CM_ "AUTOGENERATED FILE, DO NOT EDIT";

CM_ "gwm_haval_h6_mk3.dbc starts here";
BO_ 96 CAR_OVERALL_SIGNALS2: 64 XXX
 SG_ CRC1 : 7|8@0+ (1,0) [0|255] "" XXX
 SG_ COUNTER1 : 59|4@0+ (1,0) [0|15] "" XXX
 SG_ CRC2 : 71|8@0+ (1,0) [0|255] "" XXX
 SG_ GAS_POSITION : 79|8@0+ (0.393700787,0) [0|255] "%" XXX
 SG_ BRAKE_SIGNAL : 86|1@0+ (1,0) [0|1] "" XXX
 SG_ ACC_GAS_POSITION : 103|8@0+ (0.393700787,0) [0|255] "%" XXX
 SG_ COUNTER2 : 123|4@0+ (1,0) [0|15] "" XXX
 SG_ CRC3 : 135|8@0+ (1,0) [0|255] "" XXX
 SG_ COUNTER3 : 187|4@0+ (1,0) [0|15] "" XXX

BO_ 147 IMPRECISE_SPEED_INFORMATION: 8 XXX
 SG_ IMPRECISE_SPEED : 15|8@0+ (3.5,0) [0|255] "kph" XXX
 SG_ COUNTER : 59|4@0+ (1,0) [0|15] "" XXX

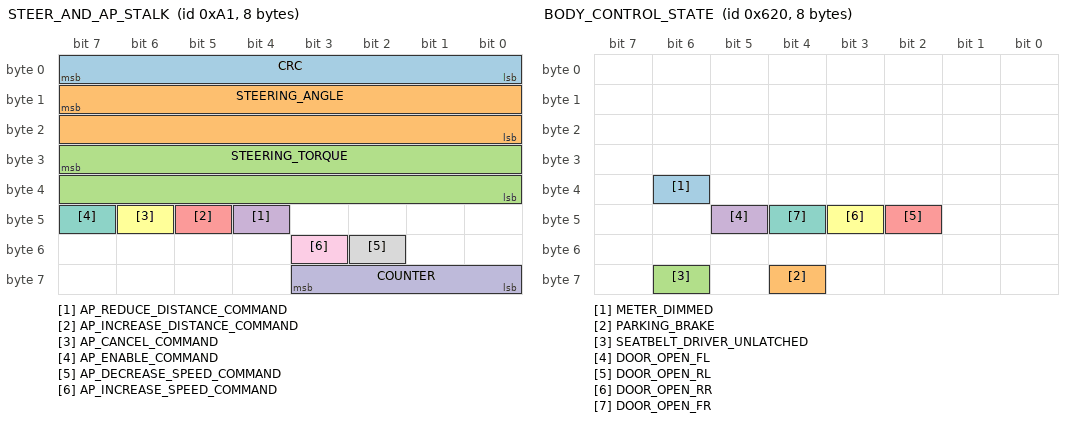
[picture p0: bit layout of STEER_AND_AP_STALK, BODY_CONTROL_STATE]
BO_ 161 STEER_AND_AP_STALK: 8 XXX
 SG_ CRC : 7|8@0+ (1,0) [0|255] "" XXX
 SG_ STEERING_ANGLE : 15|16@0+ (0.05,0) [0|65535] "degs" XXX
 SG_ STEERING_TORQUE : 31|16@0+ (1,0) [0|65535] "??" XXX
 SG_ AP_REDUCE_DISTANCE_COMMAND : 44|1@0+ (1,0) [0|1] "" XXX
 SG_ AP_INCREASE_DISTANCE_COMMAND : 45|1@0+ (1,0) [0|1] "AUTOPILOT_STALK" XXX
 SG_ AP_CANCEL_COMMAND : 46|1@0+ (1,0) [0|1] "" XXX
 SG_ AP_ENABLE_COMMAND : 47|1@0+ (1,0) [0|1] "" XXX
 SG_ AP_DECREASE_SPEED_COMMAND : 50|1@0+ (1,0) [0|1] "" XXX
 SG_ AP_INCREASE_SPEED_COMMAND : 51|1@0+ (1,0) [0|1] "" XXX
 SG_ COUNTER : 59|4@0+ (1,0) [0|255] "" XXX

BO_ 259 SPEED: 64 XXX
 SG_ CRC : 199|8@0+ (1,0) [0|255] "" XXX
 SG_ ODD_GAS_POSITION : 231|8@0+ (1,0) [0|255] "" XXX
 SG_ SPEED : 239|8@0+ (1,0) [0|255] "Khp" XXX
 SG_ COUNTER2 : 251|4@0+ (1,0) [0|15] "" XXX

BO_ 273 UNDEFINED_2: 8 XXX
 SG_ CRC : 7|8@0+ (1,0) [0|255] "" XXX
 SG_ COUNTER : 59|4@0+ (1,0) [0|15] "" XXX

BO_ 288 BRAKE2: 64 XXX
 SG_ CRC : 7|8@0+ (1,0) [0|255] "" XXX
 SG_ ODD_BRAKE_PRESSURE : 39|8@0+ (1,-27) [0|255] "" XXX
 SG_ COUNTER : 59|4@0+ (1,0) [0|15] "" XXX

BO_ 303 CAR_OVERALL_SIGNALS: 64 XXX
 SG_ CRC1 : 71|8@0+ (1,0) [0|255] "" XXX
 SG_ DRIVE_MODE_SIGNAL : 73|1@0+ (1,0) [0|1] "" XXX
 SG_ GAS_SIGNAL : 86|1@0+ (1,0) [0|1] "" XXX
 SG_ COUNTER1 : 123|4@0+ (1,0) [0|15] "" XXX
 SG_ CRC2 : 135|8@0+ (1,0) [0|255] "" XXX
 SG_ DRIVER_MODE_SIGNAL2 : 161|1@0+ (1,0) [0|1] "" XXX
 SG_ DRIVE_MODE_P : 162|1@0+ (1,0) [0|1] "" XXX
 SG_ DRIVE_MODE_D : 163|1@0+ (1,0) [0|1] "" XXX
 SG_ DRIVE_MODE_SIGNAL3 : 165|1@0+ (1,0) [0|1] "" XXX
 SG_ DRIVE_MODE : 166|2@0+ (1,0) [0|1] "" XXX
 SG_ BRAKE_SIGNAL : 176|1@0+ (1,0) [0|1] "" XXX
 SG_ COUNTER2 : 187|4@0+ (1,0) [0|15] "" XXX

BO_ 311 BRAKE: 64 XXX
 SG_ CRC1 : 71|8@0+ (1,0) [0|255] "" XXX
 SG_ COUNTER1 : 123|4@0+ (1,0) [0|15] "" XXX
 SG_ CRC2 : 135|8@0+ (1,0) [0|255] "" XXX
 SG_ BRAKE_SIGNAL1 : 152|1@0+ (1,0) [0|1] "" XXX
 SG_ BRAKE_SIGNAL2 : 155|1@0+ (1,0) [0|1] "" XXX
 SG_ COUNTER2 : 187|4@0+ (1,0) [0|15] "" XXX
 SG_ CRC3 : 199|8@0+ (1,0) [0|255] "" XXX
 SG_ BRAKE_PRESSURE : 207|13@0+ (1,0) [0|8191] "" XXX
 SG_ COUNTER3 : 251|4@0+ (1,0) [0|15] "" XXX
 SG_ CRC4 : 263|8@0+ (1,0) [0|255] "" XXX

BO_ 315 WHEEL_SPEEDS: 64 XXX
 SG_ FRONT_CRC : 7|8@0+ (1,0) [0|255] "" XXX
 SG_ FRONT_LEFT_WHEEL_SPEED : 12|13@0+ (0.05924739,0) [0|8191] "Kph" XXX
 SG_ FRONT_RIGHT_WHEEL_SPEED : 28|13@0+ (0.05924739,0) [0|8191] "Kph" XXX
 SG_ FRONT_COUNTER : 59|4@0+ (1,0) [0|15] "" XXX
 SG_ REAR_CRC : 327|8@0+ (1,0) [0|255] "" XXX
 SG_ REAR_LEFT_WHEEL_SPEED : 332|13@0+ (0.05924739,0) [0|8191] "Kph" XXX
 SG_ REAR_RIGHT_WHEEL_SPEED : 348|13@0+ (0.05924739,0) [0|8191] "Kph" XXX
 SG_ REAR_COUNTER : 379|4@0+ (1,0) [0|15] "" XXX

BO_ 323 SPEED2: 64 XXX
 SG_ NEW_SIGNAL_1 : 71|8@0+ (1,0) [0|255] "" XXX
 SG_ SPEED_REAL : 119|8@0+ (1,0) [0|255] "Kph" XXX
 SG_ COUNTER : 123|4@0+ (1,0) [0|15] "" XXX
 SG_ CRC2 : 135|8@0+ (1,0) [0|255] "" XXX

BO_ 327 NEW_MSG_147: 64 XXX

BO_ 347 NEW_MSG_15B: 64 XXX

BO_ 357 NEW_MSG_165: 8 XXX

BO_ 367 NEW_MSG_16F: 64 XXX

BO_ 412 LIGHTS: 16 XXX
 SG_ BRAKE_LIGHTS : 24|3@0+ (1,0) [0|7] "" XXX
 SG_ RIGHT_TURN_SIGNAL : 30|1@0+ (1,0) [0|1] "ON/OFF ACCORDINGLY LIGHT" XXX
 SG_ LEFT_TURN_SIGNAL : 31|1@0+ (1,0) [0|1] "ON/OFF ACCORDINGLY LIGHT" XXX

BO_ 649 DRIVE_MODE: 64 XXX
 SG_ DRIVE_MODE_ENABLED : 382|1@0+ (1,0) [0|1] "" XXX
 SG_ DRIVE_MODE_DISABLED : 383|1@0+ (1,0) [0|1] "" XXX

BO_ 683 ACC: 64 XXX
 SG_ COUNTER1 : 123|4@0+ (1,0) [0|15] "" XXX
 SG_ CRC1 : 135|8@0+ (1,0) [0|255] "" XXX
 SG_ CAR_DISTANCE_SELECTION : 170|3@0+ (1,0) [0|7] "" XXX
 SG_ ACC_SPEED_SELECTION : 183|8@0+ (1,0) [0|255] "Kph" XXX
 SG_ COUNTER2 : 187|4@0+ (1,0) [0|15] "" XXX

BO_ 714 BUTTONS: 8 XXX
 SG_ LOCK_DOORS_BUTTON : 16|1@0+ (1,0) [0|1] "" XXX

BO_ 793 DOOR_DRIVER: 16 XXX
 SG_ REQ_REVIEW_CAR_STATE : 16|1@0+ (1,0) [0|1] "" XXX
 SG_ DOOR_REAR_RIGHT_OPEN : 19|1@0+ (1,0) [0|1] "" XXX
 SG_ DOOR_FRONT_RIGHT_OPEN : 20|1@0+ (1,0) [0|1] "" XXX
 SG_ DOOR_REAR_LEFT_OPEN : 21|1@0+ (1,0) [0|1] "" XXX
 SG_ DOOR_DRIVER_OPEN : 22|1@0+ (1,0) [0|1] "" XXX

BO_ 837 DOOR_LOCK_STATES: 16 XXX
 SG_ DOOR_LOCK_STATE : 13|1@0+ (1,0) [0|1] "" XXX
 SG_ DOOR_LOCK_STATE2 : 34|1@0+ (1,0) [0|1] "" XXX

BO_ 849 SEATBELT: 16 XXX
 SG_ CRC : 7|8@0+ (1,0) [0|255] "" XXX
 SG_ SEAT_BELT_DRIVER_STATE : 11|1@0+ (1,0) [0|1] "" XXX
 SG_ SEAT_BELT_DRIVER_STATE2 : 24|1@0+ (1,0) [0|1] "" XXX
 SG_ COUNTER : 59|4@0+ (1,0) [0|15] "" XXX

BO_ 1568 BODY_CONTROL_STATE: 8 XXX
 SG_ METER_DIMMED : 38|1@0+ (1,0) [0|1] "" XXX
 SG_ PARKING_BRAKE : 60|1@0+ (1,0) [0|1] "" XXX
 SG_ SEATBELT_DRIVER_UNLATCHED : 62|1@0+ (1,0) [0|1] "" XXX
 SG_ DOOR_OPEN_FL : 45|1@0+ (1,0) [0|1] "" XXX
 SG_ DOOR_OPEN_RL : 42|1@0+ (1,0) [0|1] "" XXX
 SG_ DOOR_OPEN_RR : 43|1@0+ (1,0) [0|1] "" XXX
 SG_ DOOR_OPEN_FR : 44|1@0+ (1,0) [0|1] "" XXX

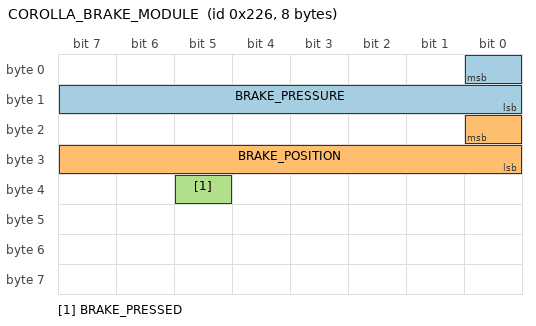
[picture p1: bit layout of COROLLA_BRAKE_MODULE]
BO_ 550 COROLLA_BRAKE_MODULE: 8 XXX
 SG_ BRAKE_PRESSURE : 0|9@0+ (1,0) [0|511] "" XXX
 SG_ BRAKE_POSITION : 16|9@0+ (1,0) [0|511] "" XXX
 SG_ BRAKE_PRESSED : 37|1@0+ (1,0) [0|1] "" XXX

CM_ SG_ 96 GAS_POSITION "0 - 100%";
CM_ SG_ 96 BRAKE_SIGNAL "1 = BRAKE PRESSED";
CM_ SG_ 96 ACC_GAS_POSITION "0 - 100% | WHEN ACC REMAINS INFORMATION";
CM_ SG_ 147 IMPRECISE_SPEED "lower precision, reverse is positive as well";
CM_ SG_ 161 STEERING_ANGLE "0 CENTER, NO LEFT / RIGHT SIGNAL";
CM_ SG_ 161 STEERING_TORQUE "Peak identified 3680, 0 = stopped";
CM_ SG_ 161 AP_REDUCE_DISTANCE_COMMAND "AUTOPILOT STALK";
CM_ SG_ 161 AP_CANCEL_COMMAND "AUTOPILOT STALK - FRONT MOVEMENT = CANCEL COMMAND";
CM_ SG_ 161 AP_ENABLE_COMMAND "AUTOPILOT STALK - REAR MOVEMENT = ENABLE COMMAND";
CM_ SG_ 161 AP_DECREASE_SPEED_COMMAND "AUTOPILOT STALK - MOVEMENT";
CM_ SG_ 161 AP_INCREASE_SPEED_COMMAND "AUTOPILOT STALK - DOWN MOVEMENT]";
CM_ SG_ 259 UNDEFINED_ACCUMULATOR "WHEN ELETRIC MODE = 0, PERHAPS COMBUSTION ENGINE";
CM_ SG_ 259 UNDEFINED_COUNTER "0 WHEN ELECTRIC, PERHAPS COMBUSTION ENGINE";
CM_ SG_ 259 ODD_GAS_POSITION "17 = 0, 253 = FULL, SOMETIMES 4";
CM_ SG_ 259 SPEED "PRECISE, KPH, DASHBOARD SPEED, BIT LOWER THAN GPS SPEED";
CM_ SG_ 288 ODD_BRAKE_PRESSURE "ODD BRAKE PRESSURE, NEGATIVE/OFFSET";
CM_ SG_ 299 AP_UNDEFINED_SIGNAL3 "PERHAPS HANDS ON SENSOR";
CM_ SG_ 299 AP_STATE "1 = ON | 0 = OFF";
CM_ SG_ 303 DRIVE_MODE_SIGNAL "D/R = 0 | N/P = 1";
CM_ SG_ 303 GAS_SIGNAL "1 = GAS PRESSED";
CM_ SG_ 303 DRIVER_MODE_SIGNAL2 "D/R = 1 | N/P=0";
CM_ SG_ 303 DRIVE_MODE_SIGNAL3 "P/R = 1 | P/N = 0";
CM_ SG_ 303 DRIVE_MODE "0 = P | 1 = D | 2 = N | 3 = R (GOOD SIGNAL)";
CM_ SG_ 303 BRAKE_SIGNAL "1 BRAKE PRESSED";
CM_ SG_ 311 BRAKE_SIGNAL1 "0 = NO | 1 = BRAKE PRESSED";
CM_ SG_ 311 BRAKE_SIGNAL2 "0 NO | 1 = BRAKE PRESSED";
CM_ SG_ 311 BRAKE_PRESSURE "MAX PRESSURE IDENTIFIED = 4184 | 0 = NO PRESSURE";
CM_ SG_ 315 FRONT_LEFT_WHEEL_SPEED "Based on the car's dashboard speed";
CM_ SG_ 315 FRONT_RIGHT_WHEEL_SPEED "Based on the car's dashboard speed";
CM_ SG_ 315 FRONT_DISTANCE_ACCUMULATOR "?? doubts";
CM_ SG_ 315 REAR_LEFT_WHEEL_SPEED "Based on the car's dashboard speed";
CM_ SG_ 315 REAR_RIGHT_WHEEL_SPEED "Based on the car's dashboard speed";
CM_ SG_ 315 REAR_DISTANCE_ACCUMULATOR "PULSES";
CM_ SG_ 323 SPEED_REAL "PRECISE, EQUAL GPS SPEED";
CM_ SG_ 412 BRAKE_LIGHTS "POSSIBLE 3 DIFFERENT LIGHTS";
CM_ SG_ 412 LEFT_TURN_SIGNAL "ON/OFF ACCORDINGLY LIGHT";
CM_ BO_ 573 "APPEARS TO HAVE GOOD MOVING INFORMATION";
CM_ BO_ 649 "FRONT";
CM_ SG_ 649 DRIVE_MODE_ENABLED "DRIVE = 1 | OTHER MODES = 0";
CM_ SG_ 649 DRIVE_MODE_DISABLED "D = 0 | OTHER MODES = 0";
CM_ SG_ 683 CAR_DISTANCE_SELECTION "AUTOPILOT CAR DISTANCE SELECTED BY DRIVER, OPTIONS 1, 2, 3, 4";
CM_ BO_ 696 "POSSIBLE RELATED TO ACC OR ENGINE";
CM_ SG_ 714 LOCK_DOORS_BUTTON "1 = PRESSED";
CM_ SG_ 837 DOOR_LOCK_STATE "0 = LOCKED / 1 = UNLOCKED";
CM_ SG_ 837 DOOR_LOCK_STATE2 "0 = LOCKED / 1 = UNLOCKED";
CM_ SG_ 849 SEAT_BELT_DRIVER_STATE "0 = Fastened / 1 = Released";
CM_ SG_ 849 SEAT_BELT_DRIVER_STATE2 "0 = Fastened / 1 = Released";
